# N572F065_v3 register map
File version: 1.0
Registers are 32-bit, read-write, reset 0x0 unless marked. A register's access mark holds for its fields unless they carry their own. Offsets are from the block's base; [hi:lo] are bit positions; {n}, {i} and the like mark numbered series.

## PWM — PWM Register Map
Base 0x40040000
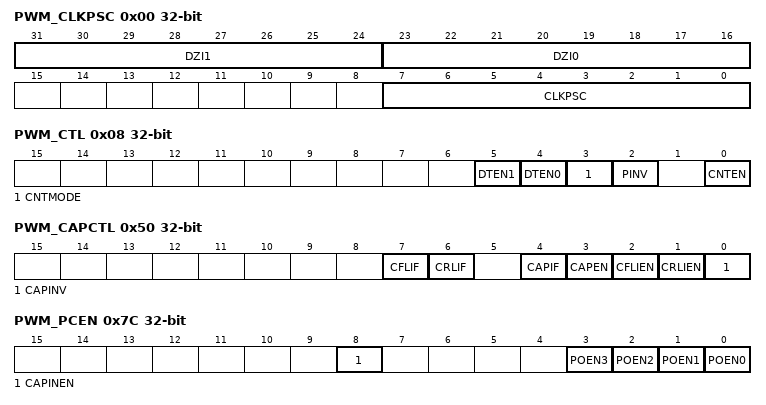
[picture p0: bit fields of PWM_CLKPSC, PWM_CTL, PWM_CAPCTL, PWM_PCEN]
0x00 PWM_CLKPSC — PWM Prescaler Register
  [31:24] DZI1 — Dead Zone Interval Register 1. These 8 bits determine dead zone length. The unit time of dead zone length is that from clock selector.
  [23:16] DZI0 — Dead Zone Interval Register 0. These 8 bits determine dead zone length. The unit time of dead zone length is that from clock selector.
  [7:0] CLKPSC — Clock Prescaler For PWM Timer. Clock input is divided by (CLKPSC + 1)
0x04 PWM_CLKDIV — PWM Clock Select Register
  [2:0] CLKDIV — PWM Timer Clock Source Selection. Value : Input clock divided by. 000 : 2. 001 : 4. 010 : 8. 011 : 16. 1xx : 1
0x08 PWM_CTL — PWM Control Register
  [5] DTEN1 — Dead-Zone 1 Generator Enable/Disable
    0=Disable; 1=Enable
  [4] DTEN0 — Dead-Zone 0 Generator Enable/Disable
    0=Disable; 1=Enable
  [3] CNTMODE — PWM-Timer Auto-Reload/One-Shot Mode
    0=One-Shot Mode; 1=Auto-reload Mode
  [2] PINV — PWM-Timer Output Inverter ON/OFF
    0=Inverter OFF; 1=Inverter ON
  [0] CNTEN — PWM-Timer Enable
    0=Stop PWM-Timer Running; 1=Enable PWM-Timer
0x0C PWM_PERIOD
  [15:0] PERIOD — PWM Counter/Timer Reload Value. PERIOD determines the PWM period.
{0x10+0xC*i} PWM_CMPDAT{i} (i=0..3) — PWM Comparator Register 0
  [15:0] CMP — PWM Comparator Register. CMP determines the PWM duty ratio. Assumption: PWM output initial is high. Note2: Any write to CMP will take effect in next PWM cycle.
0x14 PWM_CNT ro — PWM Counter Register
  [15:0] CNT — PWM Counter Register. Reports the current value of the 16-bit down counter.
0x40 PWM_INTEN — PWM Interrupt Enable Register
  [0] PIEN — PWM Timer Interrupt Enable
    0=Disable; 1=Enable
0x44 PWM_INTSTS — PWM Interrupt Flag Register
  [0] PIF — PWM Timer Interrupt Flag. Flag is set by hardware when PWM down counter reaches zero, software can clear this bit by writing '1' to it.
0x50 PWM_CAPCTL — Capture Control Register
  [7] CFLIF — PWM_FCAPDAT Latched Indicator Bit. When input channel has a falling transition, PWM_FCAPDAT was latched with the value of PWM down-counter and this bit is set by hardware, software can clear this bit by writing a zero to it.
  [6] CRLIF — PWM_RCAPDAT Latched Indicator Bit. When input channel has a rising transition, PWM_RCAPDAT was latched with the value of PWM down-counter and this bit is set by hardware, software can clear this bit by writing a zero to it.
  [4] CAPIF — Capture Interrupt Indication Flag. Note:If this bit is "1", PWM counter will not be reloaded when next capture interrupt occurs.
  [3] CAPEN — Capture Channel Input Transition Enable/Disable. When enabled, Capture function latches the PMW-counter to RCAPDAT (Rising latch) and FCAPDAT (Falling latch) registers on input edge transition. When disabled, Capture function is inactive as is interrupt.
    0=Disable capture function; 1=Enable capture function
  [2] CFLIEN — Falling Latch Interrupt Enable ON/OFF. When enabled, capture block generates an interrupt on falling edge of input.
    0=Disable falling latch interrupt; 1=Enable falling latch interrupt
  [1] CRLIEN — Rising Latch Interrupt Enable ON/OFF. When enabled, capture block generates an interrupt on rising edge of input.
    0=Disable rising latch interrupt; 1=Enable rising latch interrupt
  [0] CAPINV — Inverter ON/OFF
    0=Inverter OFF; 1=Inverter ON. Reverse the input signal from GPIO before fed to Capture timer
0x58 PWM_RCAPDAT ro — Capture Rising Latch Register
  [15:0] RCAPDAT — Capture Rising Latch Register. In Capture mode, this register is latched with the value of the PWM counter on a rising edge of the input signal.
0x5C PWM_FCAPDAT ro — Capture Falling Latch Register
  [15:0] FCAPDAT — Capture Falling Latch Register. In Capture mode, this register is latched with the value of the PWM counter on a falling edge of the input signal.
0x7C PWM_PCEN — PWM Output and Capture Input Enable Register
  [8] CAPINEN — Capture Input Enable Register
    0=OFF (PB.12 pin input disconnected from Capture block); 1=ON (PB.12 pin, if in PWM alternative function, will be configured as an input and fed to capture function)
  [3] POEN3 — PWM3 Output Enable Register. Note: The corresponding GPIO pin also must be switched to PWM function (refer to SYS_GPB_MFP Error! Reference source not found.)
    0=Disable PWM3 output to pin; 1=Enable PWM3 output to pin
  [2] POEN2 — PWM2 Output Enable Register. Note: The corresponding GPIO pin also must be switched to PWM function (refer to SYS_GPA_MFP Error! Reference source not found.)
    0=Disable PWM2 output to pin; 1=Enable PWM2 output to pin
  [1] POEN1 — PWM1 Output Enable Register. Note: The corresponding GPIO pin also must be switched to PWM function (refer to SYS_GPA_MFP Error! Reference source not found.)
    0=Disable PWM1 output to pin; 1=Enable PWM1 output to pin
  [0] POEN0 — PWM0 Output Enable Register. Note: The corresponding GPIO pin also must be switched to PWM function (refer to SYS_GPA_MFP Error! Reference source not found.)
    0=Disable PWM0 output to pin; 1=Enable PWM0 output to pin
